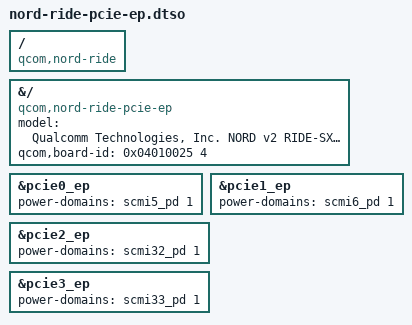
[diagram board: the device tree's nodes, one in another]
// SPDX-License-Identifier: BSD-3-Clause
/*
 * Copyright (c) Qualcomm Technologies, Inc. and/or its subsidiaries.
 */

/dts-v1/;
/plugin/;

/ {
	compatible = "qcom,nord-ride", "qcom,nord";
};

&{/} {
	model = "Qualcomm Technologies, Inc. NORD v2 RIDE-SX PCIe EP";
	compatible = "qcom,nord-ride-pcie-ep", "qcom,sa8x97p-qam-ride-sx",
		     "qcom,nord-ride", "qcom,nord";
	qcom,board-id = <0x04010025 4>;
};

&pcie0_ep {
	power-domains = <&scmi5_pd 1>;
	power-domain-names = "power";
	status = "okay";
};

&pcie1_ep {
	power-domains = <&scmi6_pd 1>;
	power-domain-names = "power";
};

&pcie2_ep {
	power-domains = <&scmi32_pd 1>;
	power-domain-names = "power";
};

&pcie3_ep {
	power-domains = <&scmi33_pd 1>;
	power-domain-names = "power";
};
